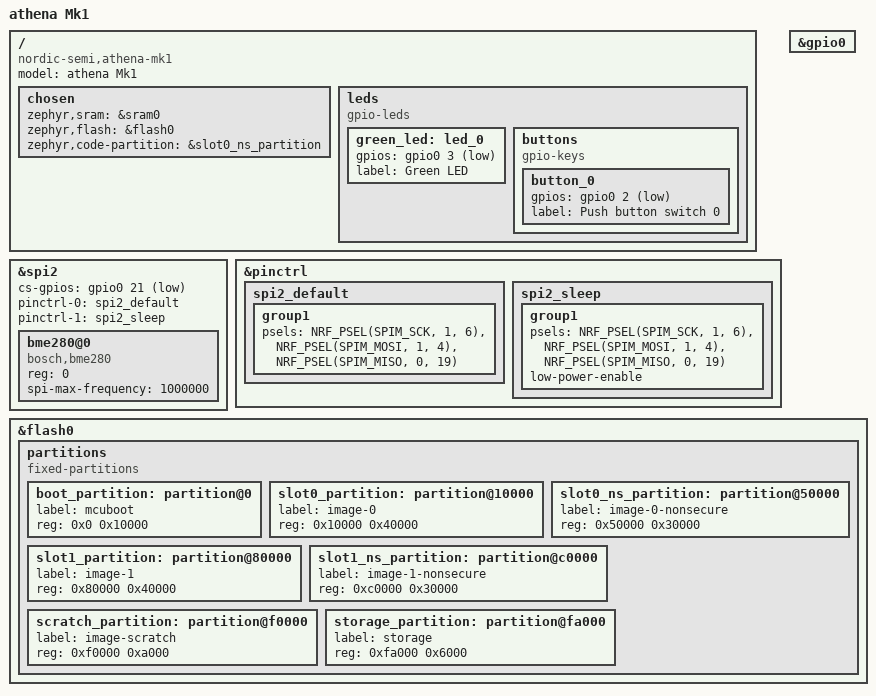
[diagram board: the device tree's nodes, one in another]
// Copyright (c) 2023 Nordic Semiconductor ASA
// SPDX-License-Identifier: Apache-2.0

/dts-v1/;
#include <nordic/nrf5340_cpuappns_qkaa.dtsi>

/ {
	model = "athena Mk1";
	compatible = "nordic-semi,athena-mk1";

	chosen {
		zephyr,sram = &sram0;
		zephyr,flash = &flash0;
		zephyr,code-partition = &slot0_ns_partition;
	};

	leds {
		compatible = "gpio-leds";
		green_led: led_0 {
			gpios = <&gpio0 3 GPIO_ACTIVE_LOW>;
			label = "Green LED";
		};

		buttons {
			compatible = "gpio-keys";
			button_0: button_0 {
				gpios = <&gpio0 2 (GPIO_PULL_UP | GPIO_ACTIVE_LOW)>;
				label = "Push button switch 0";
			};
		};



	};
};

&spi2 {
	status = "okay";
	cs-gpios = <&gpio0 21 GPIO_ACTIVE_LOW>;
	pinctrl-0 = <&spi2_default>;
	pinctrl-1 = <&spi2_sleep>;
	pinctrl-names = "default", "sleep";
	bme280@0 {
		compatible = "bosch,bme280";
		reg = <0>;
		spi-max-frequency = <1000000>; /* conservatively set to 1MHz */
	};
};
&pinctrl {
	spi2_default: spi2_default {
			group1 {
					psels = <NRF_PSEL(SPIM_SCK, 1, 6)>,
							<NRF_PSEL(SPIM_MOSI, 1, 4)>,
							<NRF_PSEL(SPIM_MISO, 0, 19)>;
			};
	};
	spi2_sleep: spi2_sleep {
			group1 {
					psels = <NRF_PSEL(SPIM_SCK, 1, 6)>,
							<NRF_PSEL(SPIM_MOSI, 1, 4)>,
							<NRF_PSEL(SPIM_MISO, 0, 19)>;
					low-power-enable;
			};
	};
};

&gpio0 {
	status = "okay";
};


&flash0 {
	partitions {
		compatible = "fixed-partitions";
		#address-cells = <1>;
		#size-cells = <1>;

		boot_partition: partition@0 {
			label = "mcuboot";
			reg = <0x0 0x10000>;
		};
		slot0_partition: partition@10000 {
			label = "image-0";
			reg = <0x10000 0x40000>;
		};
		slot0_ns_partition: partition@50000 {
			label = "image-0-nonsecure";
			reg = <0x50000 0x30000>;
		};
		slot1_partition: partition@80000 {
			label = "image-1";
			reg = <0x80000 0x40000>;
		};
		slot1_ns_partition: partition@c0000 {
			label = "image-1-nonsecure";
			reg = <0xc0000 0x30000>;
		};
		scratch_partition: partition@f0000 {
			label = "image-scratch";
			reg = <0xf0000 0xa000>;
		};
		storage_partition: partition@fa000 {
			label = "storage";
			reg = <0xfa000 0x6000>;
		};
	};
};

